AUTOSAR XML (schema 4-3-0)
package /CollisionDetectionApplicationLayer/ApplicationPackage
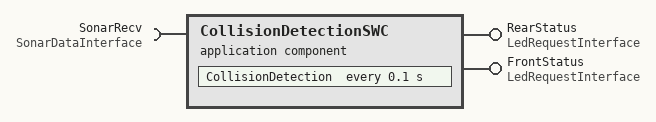
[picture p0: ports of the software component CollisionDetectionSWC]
  application sw component type CollisionDetectionSWC
    provide port RearStatus: provided-interface=LedRequestInterface
    provide port FrontStatus: provided-interface=LedRequestInterface
    require port SonarRecv: required-interface=SonarDataInterface
    behavior CollisionDetectionSWCBehaviour: data-type-mapping=TypeMappings, handle-termination-and-restart=NO-SUPPORT
      timing event CollisionDetection_timingEvent_0_1: start-on-event=CollisionDetection, period=0.1
      runnable CollisionDetection: symbol=collisionDetection
        data-read-access:
          access dataReadAccess_CollisionDetection_SonarRecv_distance: accessed-variable=SonarRecv.distance
        data-write-access:
          access dataWriteAccess_CollisionDetection_RearStatus_Status: accessed-variable=RearStatus.Status
          access dataWriteAccess_CollisionDetection_FrontStatus_Status: accessed-variable=FrontStatus.Status
  swc implementation CollisionDetectionSWCImpl: programming-language=C, vendor-id=0, behavior=CollisionDetectionSWCBehaviour
    code-descriptors:
      code src: artifact-descriptors=autosar-engineering-object={short-label=artifactDescriptor, category=artifactDescriptorCategory}
    resource consumption resourceConsumption
